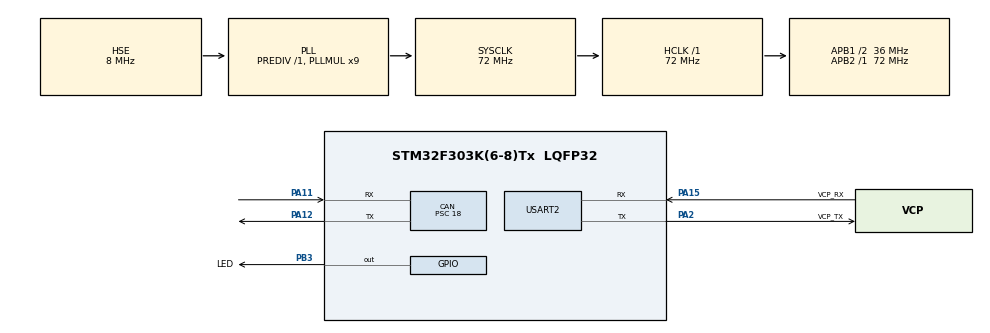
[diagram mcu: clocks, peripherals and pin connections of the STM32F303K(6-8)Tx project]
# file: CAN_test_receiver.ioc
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CAN.BS1=CAN_BS1_2TQ
CAN.CalculateBaudRate=500000
CAN.CalculateTimeBit=2000
CAN.CalculateTimeQuantum=500.0
CAN.Prescaler=18
Mcu.Family=STM32F3
Mcu.Name=STM32F303K(6-8)Tx
Mcu.Package=LQFP32
NVIC.CAN_RX0_IRQn=true\:0\:0\:false\:false\:true\:true\:true\:true
NVIC.PriorityGroup=NVIC_PRIORITYGROUP_4
PA11.GPIO_PuPd=GPIO_PULLUP
PA11.Mode=CAN_Activate
PA11.Signal=CAN_RX
PA12.Mode=CAN_Activate
PA12.Signal=CAN_TX
PA13.GPIO_Label=SWDIO
PA13.Mode=Serial_Wire
PA13.Signal=SYS_JTMS-SWDIO
PA14.GPIO_Label=SWCLK
PA14.Mode=Serial_Wire
PA14.Signal=SYS_JTCK-SWCLK
PA15.GPIO_Label=VCP_RX
PA15.Mode=Asynchronous
PA15.Signal=USART2_RX
PA2.GPIO_Label=VCP_TX
PA2.Mode=Asynchronous
PA2.Signal=USART2_TX
PB3.GPIO_Label=LED
PB3.Signal=GPIO_Output
PF0\ /\ OSC_IN.GPIO_Label=MCO
PF0\ /\ OSC_IN.Mode=HSE-External-Clock-Source
PF0\ /\ OSC_IN.Signal=RCC_OSC_IN
ProjectManager.HeapSize=0x200
ProjectManager.StackSize=0x400
ProjectManager.TargetToolchain=STM32CubeIDE
RCC.AHBFreq_Value=72000000
RCC.APB1CLKDivider=RCC_HCLK_DIV2
RCC.APB1Freq_Value=36000000
RCC.APB1TimFreq_Value=72000000
RCC.APB2Freq_Value=72000000
RCC.APB2TimFreq_Value=72000000
RCC.CortexFreq_Value=72000000
RCC.HCLKFreq_Value=72000000
RCC.HSE_VALUE=8000000
RCC.HSI_VALUE=8000000
RCC.PLLMUL=RCC_PLL_MUL9
RCC.PLLSourceVirtual=RCC_PLLSOURCE_HSE
RCC.SYSCLKFreq_VALUE=72000000
RCC.SYSCLKSourceVirtual=RCC_SYSCLKSOURCE_PLLCLK
USART2.VirtualMode-Asynchronous=VM_ASYNC
board=NUCLEO-F303K8

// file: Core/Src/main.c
/* USER CODE BEGIN Header */
/**
  ******************************************************************************
  * @file           : main.c
  * @brief          : Main program body
  ******************************************************************************
  * @attention
  *
  * Copyright (c) 2024 STMicroelectronics.
  * All rights reserved.
  *
  * This software is licensed under terms that can be found in the LICENSE file
  * in the root directory of this software component.
  * If no LICENSE file comes with this software, it is provided AS-IS.
  *
  ******************************************************************************
  */
/* USER CODE END Header */
#include "main.h"

CAN_HandleTypeDef hcan;

UART_HandleTypeDef huart2;

void SystemClock_Config(void);
static void MX_GPIO_Init(void);
static void MX_USART2_UART_Init(void);
static void MX_CAN_Init(void);

/* USER CODE BEGIN 0 */
CAN_RxHeaderTypeDef RxHeader;
uint8_t CAN_Buf[1];
uint32_t TxMailbox;
/* USER CODE END 0 */

int main(void)
{

  /* MCU Configuration--------------------------------------------------------*/

  /* Reset of all peripherals, Initializes the Flash interface and the Systick. */
  HAL_Init();

  /* Configure the system clock */
  SystemClock_Config();

  /* Initialize all configured peripherals */
  MX_GPIO_Init();
  MX_USART2_UART_Init();
  MX_CAN_Init();
  /* USER CODE BEGIN 2 */
  if (HAL_CAN_ActivateNotification(&hcan, CAN_IT_RX_FIFO0_MSG_PENDING) != HAL_OK) {
	  Error_Handler();
  }
  /* USER CODE END 2 */

  /* Infinite loop */
  while (1)
  {

  }
}

void SystemClock_Config(void)
{
  RCC_OscInitTypeDef RCC_OscInitStruct = {0};
  RCC_ClkInitTypeDef RCC_ClkInitStruct = {0};

  /** Initializes the RCC Oscillators according to the specified parameters
  * in the RCC_OscInitTypeDef structure.
  */
  RCC_OscInitStruct.OscillatorType = RCC_OSCILLATORTYPE_HSE;
  RCC_OscInitStruct.HSEState = RCC_HSE_BYPASS;
  RCC_OscInitStruct.HSEPredivValue = RCC_HSE_PREDIV_DIV1;
  RCC_OscInitStruct.HSIState = RCC_HSI_ON;
  RCC_OscInitStruct.PLL.PLLState = RCC_PLL_ON;
  RCC_OscInitStruct.PLL.PLLSource = RCC_PLLSOURCE_HSE;
  RCC_OscInitStruct.PLL.PLLMUL = RCC_PLL_MUL9;
  if (HAL_RCC_OscConfig(&RCC_OscInitStruct) != HAL_OK)
  {
    Error_Handler();
  }

  /** Initializes the CPU, AHB and APB buses clocks
  */
  RCC_ClkInitStruct.ClockType = RCC_CLOCKTYPE_HCLK|RCC_CLOCKTYPE_SYSCLK
                              |RCC_CLOCKTYPE_PCLK1|RCC_CLOCKTYPE_PCLK2;
  RCC_ClkInitStruct.SYSCLKSource = RCC_SYSCLKSOURCE_PLLCLK;
  RCC_ClkInitStruct.AHBCLKDivider = RCC_SYSCLK_DIV1;
  RCC_ClkInitStruct.APB1CLKDivider = RCC_HCLK_DIV2;
  RCC_ClkInitStruct.APB2CLKDivider = RCC_HCLK_DIV1;

  if (HAL_RCC_ClockConfig(&RCC_ClkInitStruct, FLASH_LATENCY_2) != HAL_OK)
  {
    Error_Handler();
  }
}

static void MX_CAN_Init(void)
{

  hcan.Instance = CAN;
  hcan.Init.Prescaler = 18;
  hcan.Init.Mode = CAN_MODE_NORMAL;
  hcan.Init.SyncJumpWidth = CAN_SJW_1TQ;
  hcan.Init.TimeSeg1 = CAN_BS1_2TQ;
  hcan.Init.TimeSeg2 = CAN_BS2_1TQ;
  hcan.Init.TimeTriggeredMode = DISABLE;
  hcan.Init.AutoBusOff = DISABLE;
  hcan.Init.AutoWakeUp = DISABLE;
  hcan.Init.AutoRetransmission = DISABLE;
  hcan.Init.ReceiveFifoLocked = DISABLE;
  hcan.Init.TransmitFifoPriority = DISABLE;
  if (HAL_CAN_Init(&hcan) != HAL_OK)
  {
    Error_Handler();
  }

}

static void MX_USART2_UART_Init(void)
{

  huart2.Instance = USART2;
  huart2.Init.BaudRate = 38400;
  huart2.Init.WordLength = UART_WORDLENGTH_8B;
  huart2.Init.StopBits = UART_STOPBITS_1;
  huart2.Init.Parity = UART_PARITY_NONE;
  huart2.Init.Mode = UART_MODE_TX_RX;
  huart2.Init.HwFlowCtl = UART_HWCONTROL_NONE;
  huart2.Init.OverSampling = UART_OVERSAMPLING_16;
  huart2.Init.OneBitSampling = UART_ONE_BIT_SAMPLE_DISABLE;
  huart2.AdvancedInit.AdvFeatureInit = UART_ADVFEATURE_NO_INIT;
  if (HAL_UART_Init(&huart2) != HAL_OK)
  {
    Error_Handler();
  }

}

static void MX_GPIO_Init(void)
{
  GPIO_InitTypeDef GPIO_InitStruct = {0};

  /* GPIO Ports Clock Enable */
  __HAL_RCC_GPIOF_CLK_ENABLE();
  __HAL_RCC_GPIOA_CLK_ENABLE();
  __HAL_RCC_GPIOB_CLK_ENABLE();

  /*Configure GPIO pin Output Level */
  HAL_GPIO_WritePin(LED_GPIO_Port, LED_Pin, GPIO_PIN_RESET);

  /*Configure GPIO pin : LED_Pin */
  GPIO_InitStruct.Pin = LED_Pin;
  GPIO_InitStruct.Mode = GPIO_MODE_OUTPUT_PP;
  GPIO_InitStruct.Pull = GPIO_NOPULL;
  GPIO_InitStruct.Speed = GPIO_SPEED_FREQ_LOW;
  HAL_GPIO_Init(LED_GPIO_Port, &GPIO_InitStruct);

}

/* USER CODE BEGIN 4 */
void HAL_CAN_RxFifo0MsgPendingCallback(CAN_HandleTypeDef *hcan) {
	if (HAL_CAN_GetRxMessage(hcan, CAN_RX_FIFO0, &RxHeader, CAN_Buf) != HAL_OK) {
		Error_Handler();
	}
	if (RxHeader.StdId == 0x103) {
		HAL_GPIO_TogglePin(LED_GPIO_Port, LED_Pin);
	}
}
/* USER CODE END 4 */

void Error_Handler(void)
{
  __disable_irq();
  while (1)
  {
  }
}
